AUTOSAR XML (schema 00044)
package /ComponentTypes
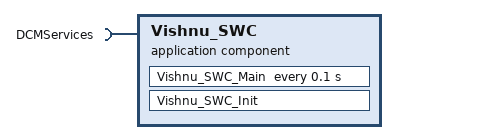
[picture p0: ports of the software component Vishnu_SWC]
  application sw component type Vishnu_SWC
    require port DCMServices: required-interface=DCMServices
      required-com-specs:
        GetSecurityLevel
        GetRequestKind
        SetActiveDiagnostic
        ResetToDefaultSession
        GetSesCtrlType
        GetActiveProtocol
    behavior Vishnu_SWC_InternalBehavior
      init event Vishnu_SWC_InitEvent: start-on-event=Vishnu_SWC_Init
      timing event TMT_Vishnu_SWC_Main: start-on-event=Vishnu_SWC_Main, period=0.1
      runnable Vishnu_SWC_Init
      runnable Vishnu_SWC_Main
  swc implementation Vishnu_SWC_Implementation: behavior=Vishnu_SWC_InternalBehavior
